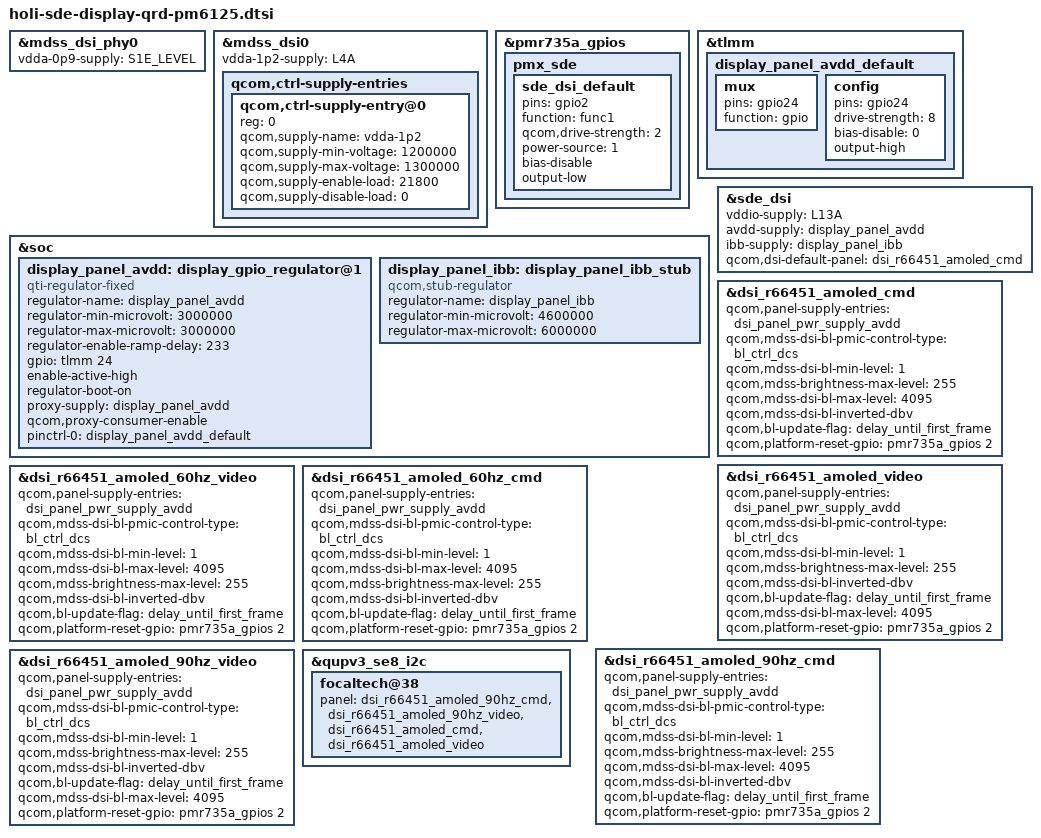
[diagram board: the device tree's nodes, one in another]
#include "holi-sde-display.dtsi"

&mdss_dsi_phy0 {
	vdda-0p9-supply = <&S1E_LEVEL>;
};

&mdss_dsi0 {
	vdda-1p2-supply = <&L4A>;

	qcom,ctrl-supply-entries {
		#address-cells = <1>;
		#size-cells = <0>;

		qcom,ctrl-supply-entry@0 {
			reg = <0>;
			qcom,supply-name = "vdda-1p2";
			qcom,supply-min-voltage = <1200000>;
			qcom,supply-max-voltage = <1300000>;
			qcom,supply-enable-load = <21800>;
			qcom,supply-disable-load = <0>;
		};
	};
};

&pmr735a_gpios {
	pmx_sde: pmx_sde {
		sde_dsi_default: sde_dsi_default {
			pins = "gpio2";
			function = "func1";
			qcom,drive-strength = <2>;
			power-source = <1>;
			bias-disable;
			output-low;
		};
	};
};

&tlmm {
	display_panel_avdd_default: display_panel_avdd_default {
		mux {
			pins = "gpio24";
			function = "gpio";
		};

		config {
			pins = "gpio24";
			drive-strength = <8>;
			bias-disable = <0>;
			output-high;
		};
	};
};

&soc {
	display_panel_avdd: display_gpio_regulator@1 {
		compatible = "qti-regulator-fixed";
		regulator-name = "display_panel_avdd";
		regulator-min-microvolt = <3000000>;
		regulator-max-microvolt = <3000000>;
		regulator-enable-ramp-delay = <233>;
		gpio = <&tlmm 24 0>;
		enable-active-high;
		regulator-boot-on;
		proxy-supply = <&display_panel_avdd>;
		qcom,proxy-consumer-enable;
		pinctrl-names = "default";
		pinctrl-0 = <&display_panel_avdd_default>;
	};

	display_panel_ibb: display_panel_ibb_stub {
		compatible = "qcom,stub-regulator";
		regulator-name = "display_panel_ibb";
		regulator-min-microvolt = <4600000>;
		regulator-max-microvolt = <6000000>;
	};
};

&sde_dsi {
	vddio-supply = <&L13A>;
	avdd-supply = <&display_panel_avdd>;
	ibb-supply = <&display_panel_ibb>;

	/delete-property/ lab-supply;
	qcom,dsi-default-panel = <&dsi_r66451_amoled_cmd>;
};

&dsi_r66451_amoled_cmd {
	qcom,panel-supply-entries = <&dsi_panel_pwr_supply_avdd>;
	qcom,mdss-dsi-bl-pmic-control-type = "bl_ctrl_dcs";
	qcom,mdss-dsi-bl-min-level = <1>;
	qcom,mdss-brightness-max-level = <255>;
	qcom,mdss-dsi-bl-max-level = <4095>;
	qcom,mdss-dsi-bl-inverted-dbv;
	qcom,bl-update-flag = "delay_until_first_frame";
	qcom,platform-reset-gpio = <&pmr735a_gpios 2 0>;
};

&dsi_r66451_amoled_video {
	qcom,panel-supply-entries = <&dsi_panel_pwr_supply_avdd>;
	qcom,mdss-dsi-bl-pmic-control-type = "bl_ctrl_dcs";
	qcom,mdss-dsi-bl-min-level = <1>;
	qcom,mdss-brightness-max-level = <255>;
	qcom,mdss-dsi-bl-inverted-dbv;
	qcom,bl-update-flag = "delay_until_first_frame";
	qcom,mdss-dsi-bl-max-level = <4095>;
	qcom,platform-reset-gpio = <&pmr735a_gpios 2 0>;
};

&dsi_r66451_amoled_60hz_video {
	qcom,panel-supply-entries = <&dsi_panel_pwr_supply_avdd>;
	qcom,mdss-dsi-bl-pmic-control-type = "bl_ctrl_dcs";
	qcom,mdss-dsi-bl-min-level = <1>;
	qcom,mdss-dsi-bl-max-level = <4095>;
	qcom,mdss-brightness-max-level = <255>;
	qcom,mdss-dsi-bl-inverted-dbv;
	qcom,bl-update-flag = "delay_until_first_frame";
	qcom,platform-reset-gpio = <&pmr735a_gpios 2 0>;
};

&dsi_r66451_amoled_60hz_cmd {
	qcom,panel-supply-entries = <&dsi_panel_pwr_supply_avdd>;
	qcom,mdss-dsi-bl-pmic-control-type = "bl_ctrl_dcs";
	qcom,mdss-dsi-bl-min-level = <1>;
	qcom,mdss-dsi-bl-max-level = <4095>;
	qcom,mdss-brightness-max-level = <255>;
	qcom,mdss-dsi-bl-inverted-dbv;
	qcom,bl-update-flag = "delay_until_first_frame";
	qcom,platform-reset-gpio = <&pmr735a_gpios 2 0>;
};

&dsi_r66451_amoled_90hz_cmd {
	qcom,panel-supply-entries = <&dsi_panel_pwr_supply_avdd>;
	qcom,mdss-dsi-bl-pmic-control-type = "bl_ctrl_dcs";
	qcom,mdss-dsi-bl-min-level = <1>;
	qcom,mdss-brightness-max-level = <255>;
	qcom,mdss-dsi-bl-max-level = <4095>;
	qcom,mdss-dsi-bl-inverted-dbv;
	qcom,bl-update-flag = "delay_until_first_frame";
	qcom,platform-reset-gpio = <&pmr735a_gpios 2 0>;
};

&dsi_r66451_amoled_90hz_video {
	qcom,panel-supply-entries = <&dsi_panel_pwr_supply_avdd>;
	qcom,mdss-dsi-bl-pmic-control-type = "bl_ctrl_dcs";
	qcom,mdss-dsi-bl-min-level = <1>;
	qcom,mdss-brightness-max-level = <255>;
	qcom,mdss-dsi-bl-inverted-dbv;
	qcom,bl-update-flag = "delay_until_first_frame";
	qcom,mdss-dsi-bl-max-level = <4095>;
	qcom,platform-reset-gpio = <&pmr735a_gpios 2 0>;
};

&qupv3_se8_i2c {
	focaltech@38 {
			panel = <&dsi_r66451_amoled_90hz_cmd
				&dsi_r66451_amoled_90hz_video
				&dsi_r66451_amoled_cmd
				&dsi_r66451_amoled_video>;
	};
};
